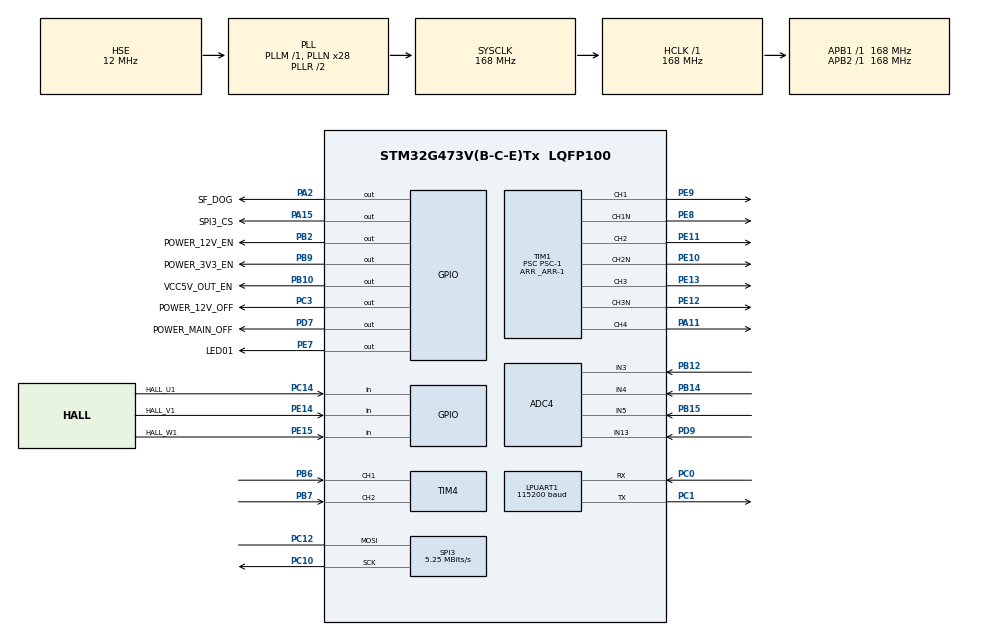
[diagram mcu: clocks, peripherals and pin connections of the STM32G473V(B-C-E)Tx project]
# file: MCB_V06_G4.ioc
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ADC4.Channel-5\#ChannelRegularConversion=ADC_CHANNEL_13
ADC4.EnableInjectedConversion=ENABLE
ADC4.ExternalTrigInjecConv=ADC_EXTERNALTRIGINJEC_T1_CC4
ADC4.InjNumberOfConversion=3
ADC4.InjectedChannel-6\#ChannelInjectedConversion=ADC_CHANNEL_3
ADC4.InjectedChannel-7\#ChannelInjectedConversion=ADC_CHANNEL_4
ADC4.InjectedChannel-8\#ChannelInjectedConversion=ADC_CHANNEL_5
ADC4.InjectedOffsetNumber-6\#ChannelInjectedConversion=ADC_OFFSET_NONE
ADC4.InjectedOffsetNumber-7\#ChannelInjectedConversion=ADC_OFFSET_NONE
ADC4.InjectedOffsetNumber-8\#ChannelInjectedConversion=ADC_OFFSET_NONE
ADC4.InjectedRank-6\#ChannelInjectedConversion=1
ADC4.InjectedRank-7\#ChannelInjectedConversion=2
ADC4.InjectedRank-8\#ChannelInjectedConversion=3
ADC4.InjectedSamplingTime-6\#ChannelInjectedConversion=ADC_SAMPLETIME_2CYCLES_5
ADC4.InjectedSamplingTime-7\#ChannelInjectedConversion=ADC_SAMPLETIME_2CYCLES_5
ADC4.InjectedSamplingTime-8\#ChannelInjectedConversion=ADC_SAMPLETIME_2CYCLES_5
ADC4.NbrOfConversionFlag=1
ADC4.OffsetNumber-5\#ChannelRegularConversion=ADC_OFFSET_NONE
ADC4.Rank-5\#ChannelRegularConversion=1
ADC4.Rank1_Channel=ADC_CHANNEL_3
ADC4.Rank2_Channel=ADC_CHANNEL_4
ADC4.Rank3_Channel=ADC_CHANNEL_5
ADC4.SamplingTime-5\#ChannelRegularConversion=ADC_SAMPLETIME_2CYCLES_5
Dma.LPUART1_RX.0.Direction=DMA_PERIPH_TO_MEMORY
Dma.LPUART1_RX.0.EventEnable=DISABLE
Dma.LPUART1_RX.0.Instance=DMA1_Channel1
Dma.LPUART1_RX.0.MemDataAlignment=DMA_MDATAALIGN_BYTE
Dma.LPUART1_RX.0.MemInc=DMA_MINC_ENABLE
Dma.LPUART1_RX.0.Mode=DMA_NORMAL
Dma.LPUART1_RX.0.PeriphDataAlignment=DMA_PDATAALIGN_BYTE
Dma.LPUART1_RX.0.PeriphInc=DMA_PINC_DISABLE
Dma.LPUART1_RX.0.Polarity=HAL_DMAMUX_REQ_GEN_RISING
Dma.LPUART1_RX.0.Priority=DMA_PRIORITY_LOW
Dma.LPUART1_RX.0.RequestNumber=1
Dma.LPUART1_RX.0.SignalID=NONE
Dma.LPUART1_RX.0.SyncEnable=DISABLE
Dma.LPUART1_RX.0.SyncPolarity=HAL_DMAMUX_SYNC_NO_EVENT
Dma.LPUART1_RX.0.SyncRequestNumber=1
Dma.LPUART1_RX.0.SyncSignalID=NONE
Dma.LPUART1_TX.1.Direction=DMA_MEMORY_TO_PERIPH
Dma.LPUART1_TX.1.EventEnable=DISABLE
Dma.LPUART1_TX.1.Instance=DMA1_Channel2
Dma.LPUART1_TX.1.MemDataAlignment=DMA_MDATAALIGN_BYTE
Dma.LPUART1_TX.1.MemInc=DMA_MINC_ENABLE
Dma.LPUART1_TX.1.Mode=DMA_NORMAL
Dma.LPUART1_TX.1.PeriphDataAlignment=DMA_PDATAALIGN_BYTE
Dma.LPUART1_TX.1.PeriphInc=DMA_PINC_DISABLE
Dma.LPUART1_TX.1.Polarity=HAL_DMAMUX_REQ_GEN_RISING
Dma.LPUART1_TX.1.Priority=DMA_PRIORITY_LOW
Dma.LPUART1_TX.1.RequestNumber=1
Dma.LPUART1_TX.1.SignalID=NONE
Dma.LPUART1_TX.1.SyncEnable=DISABLE
Dma.LPUART1_TX.1.SyncPolarity=HAL_DMAMUX_SYNC_NO_EVENT
Dma.LPUART1_TX.1.SyncRequestNumber=1
Dma.LPUART1_TX.1.SyncSignalID=NONE
Dma.Request0=LPUART1_RX
Dma.Request1=LPUART1_TX
LPUART1.BaudRate=115200
LPUART1.DataInvertParam=UART_ADVFEATURE_DATAINV_ENABLE
LPUART1.RxPinLevelInvertParam=UART_ADVFEATURE_RXINV_DISABLE
LPUART1.TxPinLevelInvertParam=UART_ADVFEATURE_TXINV_DISABLE
Mcu.Family=STM32G4
Mcu.Name=STM32G473V(B-C-E)Tx
Mcu.Package=LQFP100
Mcu.UserConstants=PSC,1;_ENCODERLINS,8192;_ARR,4200
NVIC.ADC4_IRQn=true\:0\:0\:false\:false\:true\:true\:true\:true
NVIC.DMA1_Channel2_IRQn=true\:0\:0\:false\:false\:true\:true\:true\:true
NVIC.LPUART1_IRQn=true\:0\:0\:false\:false\:true\:true\:true\:true
NVIC.PriorityGroup=NVIC_PRIORITYGROUP_4
NVIC.TIM1_UP_TIM16_IRQn=true\:0\:0\:false\:false\:true\:true\:true\:true
PA11.Signal=S_TIM1_CH4
PA13.Mode=Serial_Wire
PA13.Signal=SYS_JTMS-SWDIO
PA14.Mode=Serial_Wire
PA14.Signal=SYS_JTCK-SWCLK
PA15.GPIO_Label=SPI3_CS
PA15.GPIO_Speed=GPIO_SPEED_FREQ_LOW
PA15.Signal=GPIO_Output
PA2.GPIO_Label=SF_DOG
PA2.Signal=GPIO_Output
PB10.GPIO_Label=VCC5V_OUT_EN
PB10.Signal=GPIO_Output
PB12.Mode=IN3-Single-Ended
PB12.Signal=ADC4_IN3
PB14.Mode=IN4-Single-Ended
PB14.Signal=ADC4_IN4
PB15.Mode=IN5-Single-Ended
PB15.Signal=ADC4_IN5
PB2.GPIO_Label=POWER_12V_EN
PB2.Signal=GPIO_Output
PB6.Signal=S_TIM4_CH1
PB7.Signal=S_TIM4_CH2
PB9.GPIO_Label=POWER_3V3_EN
PB9.Signal=GPIO_Output
PC0.Mode=Asynchronous
PC0.Signal=LPUART1_RX
PC1.Mode=Asynchronous
PC1.Signal=LPUART1_TX
PC10.Mode=Simplex_Bidirectional_Master
PC10.Signal=SPI3_SCK
PC12.Mode=Simplex_Bidirectional_Master
PC12.Signal=SPI3_MOSI
PC14-OSC32_IN.GPIO_Label=HALL_U1
PC14-OSC32_IN.Signal=GPIO_Input
PC3.GPIO_Label=POWER_12V_OFF
PC3.Signal=GPIO_Output
PD7.GPIO_Label=POWER_MAIN_OFF
PD7.Signal=GPIO_Output
PD9.Mode=IN13-Single-Ended
PD9.Signal=ADC4_IN13
PE10.Mode=PWM Generation2 CH2 CH2N
PE10.Signal=TIM1_CH2N
PE11.Signal=S_TIM1_CH2
PE12.Mode=PWM Generation3 CH3 CH3N
PE12.Signal=TIM1_CH3N
PE13.Signal=S_TIM1_CH3
PE14.GPIO_Label=HALL_V1
PE14.Signal=GPIO_Input
PE15.GPIO_Label=HALL_W1
PE15.Signal=GPIO_Input
PE7.GPIO_Label=LED01
PE7.Signal=GPIO_Output
PE8.Mode=PWM Generation1 CH1 CH1N
PE8.Signal=TIM1_CH1N
PE9.Signal=S_TIM1_CH1
PF0-OSC_IN.Mode=HSE-External-Oscillator
PF0-OSC_IN.Signal=RCC_OSC_IN
PF1-OSC_OUT.Mode=HSE-External-Oscillator
PF1-OSC_OUT.Signal=RCC_OSC_OUT
ProjectManager.HeapSize=0x200
ProjectManager.StackSize=0x400
ProjectManager.TargetToolchain=Makefile
RCC.ADC12Freq_Value=168000000
RCC.ADC345Freq_Value=168000000
RCC.AHBFreq_Value=168000000
RCC.APB1Freq_Value=168000000
RCC.APB1TimFreq_Value=168000000
RCC.APB2Freq_Value=168000000
RCC.APB2TimFreq_Value=168000000
RCC.CortexFreq_Value=168000000
RCC.EXTERNAL_CLOCK_VALUE=12288000
RCC.HCLKFreq_Value=168000000
RCC.HSE_VALUE=12000000
RCC.HSI48_VALUE=48000000
RCC.HSI_VALUE=16000000
RCC.LSE_VALUE=32768
RCC.PLLN=28
RCC.PLLSourceVirtual=RCC_PLLSOURCE_HSE
RCC.SYSCLKFreq_VALUE=168000000
RCC.SYSCLKSource=RCC_SYSCLKSOURCE_PLLCLK
RCC.USBFreq_Value=168000000
RCC.VCOOutputFreq_Value=336000000
SH.S_TIM1_CH1.0=TIM1_CH1,PWM Generation1 CH1 CH1N
SH.S_TIM1_CH2.0=TIM1_CH2,PWM Generation2 CH2 CH2N
SH.S_TIM1_CH3.0=TIM1_CH3,PWM Generation3 CH3 CH3N
SH.S_TIM1_CH4.0=TIM1_CH4,Output Compare4 CH4
SH.S_TIM4_CH1.0=TIM4_CH1,Encoder_Interface
SH.S_TIM4_CH2.0=TIM4_CH2,Encoder_Interface
SPI3.BaudRatePrescaler=SPI_BAUDRATEPRESCALER_32
SPI3.CLKPhase=SPI_PHASE_2EDGE
SPI3.CRCCalculation=SPI_CRCCALCULATION_DISABLE
SPI3.CalculateBaudRate=5.25 MBits/s
SPI3.DataSize=SPI_DATASIZE_8BIT
SPI3.Direction=SPI_DIRECTION_1LINE
SPI3.Mode=SPI_MODE_MASTER
SPI3.VirtualType=VM_MASTER
TIM1.AutoReloadPreload=TIM_AUTORELOAD_PRELOAD_ENABLE
TIM1.Channel-Output\ Compare4\ CH4=TIM_CHANNEL_4
TIM1.Channel-PWM\ Generation1\ CH1\ CH1N=TIM_CHANNEL_1
TIM1.Channel-PWM\ Generation2\ CH2\ CH2N=TIM_CHANNEL_2
TIM1.Channel-PWM\ Generation3\ CH3\ CH3N=TIM_CHANNEL_3
TIM1.CounterMode=TIM_COUNTERMODE_CENTERALIGNED3
TIM1.OCMode_4=TIM_OCMODE_TOGGLE
TIM1.OCMode_PWM-PWM\ Generation1\ CH1\ CH1N=TIM_OCMODE_PWM2
TIM1.OCMode_PWM-PWM\ Generation2\ CH2\ CH2N=TIM_OCMODE_PWM2
TIM1.OCMode_PWM-PWM\ Generation3\ CH3\ CH3N=TIM_OCMODE_PWM2
TIM1.OCNPolarity_1=TIM_OCNPOLARITY_LOW
TIM1.OCNPolarity_2=TIM_OCNPOLARITY_LOW
TIM1.OCNPolarity_3=TIM_OCNPOLARITY_LOW
TIM1.PeriodNoDither=_ARR-1
TIM1.Prescaler=PSC-1
TIM1.PulseNoDither_4=200
TIM1.RepetitionCounter=2
TIM1.TIM_MasterOutputTrigger=TIM_TRGO_UPDATE
TIM1.TIM_MasterSlaveMode=TIM_MASTERSLAVEMODE_ENABLE
TIM4.Dithering=Disable
TIM4.EncoderMode=TIM_ENCODERMODE_CLOCKPLUSDIRECTION_X1
TIM4.IC1Filter=15
TIM4.IC1Polarity=TIM_ICPOLARITY_RISING
TIM4.IC2Filter=15
TIM4.PeriodNoDither=_ENCODERLINS-1
TIM4.SMS_Preload_Activation=DISABLE
VP_SYS_VS_DBSignals.Mode=DisableDeadBatterySignals
VP_TIM1_VS_ClockSourceINT.Mode=Internal
board=custom

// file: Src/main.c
/* USER CODE BEGIN Header */
/**
  ******************************************************************************
  * @file           : main.c
  * @brief          : Main program body
  ******************************************************************************
  * @attention
  *
  * Copyright (c) 2023 STMicroelectronics.
  * All rights reserved.
  *
  * This software is licensed under terms that can be found in the LICENSE file
  * in the root directory of this software component.
  * If no LICENSE file comes with this software, it is provided AS-IS.
  *
  ******************************************************************************
  */
/* USER CODE END Header */
#include "main.h"
#include "adc.h"
#include "dma.h"
#include "usart.h"
#include "spi.h"
#include "tim.h"
#include "gpio.h"

/* USER CODE BEGIN Includes */
#include "debuglog.h"
/* USER CODE END Includes */

void SystemClock_Config(void);

/* USER CODE BEGIN 0 */
extern void svpwm_testfunc(void);

/* USER CODE END 0 */

int main(void)
{

  /* MCU Configuration--------------------------------------------------------*/

  /* Reset of all peripherals, Initializes the Flash interface and the Systick. */
  HAL_Init();

  /* Configure the system clock */
  SystemClock_Config();

  /* Initialize all configured peripherals */
  MX_GPIO_Init();
  MX_DMA_Init();
  MX_SPI3_Init();
  MX_TIM1_Init();
  MX_ADC4_Init();
  MX_TIM4_Init();
  MX_LPUART1_UART_Init();
  /* USER CODE BEGIN 2 */
  HAL_Delay(800);
  USER_DEBUG_NORMAL("Hello world\n");
  // user_board_init();
  /* USER CODE END 2 */

  /* Infinite loop */
  /* USER CODE BEGIN WHILE */
  while (1)
  {
    // do_taskcalls();
    HAL_GPIO_TogglePin(SF_DOG_GPIO_Port,SF_DOG_Pin);
    static unsigned short count;
    if (count++>200)
    {
      count = 0;
      HAL_GPIO_TogglePin(LED01_GPIO_Port,LED01_Pin);
      USER_DEBUG_NORMAL(".\n");
    }
    svpwm_testfunc();
    HAL_Delay(1);
    /* USER CODE END WHILE */

  }
}

void SystemClock_Config(void)
{
  RCC_OscInitTypeDef RCC_OscInitStruct = {0};
  RCC_ClkInitTypeDef RCC_ClkInitStruct = {0};

  /** Configure the main internal regulator output voltage
  */
  HAL_PWREx_ControlVoltageScaling(PWR_REGULATOR_VOLTAGE_SCALE1_BOOST);

  /** Initializes the RCC Oscillators according to the specified parameters
  * in the RCC_OscInitTypeDef structure.
  */
  RCC_OscInitStruct.OscillatorType = RCC_OSCILLATORTYPE_HSE;
  RCC_OscInitStruct.HSEState = RCC_HSE_ON;
  RCC_OscInitStruct.PLL.PLLState = RCC_PLL_ON;
  RCC_OscInitStruct.PLL.PLLSource = RCC_PLLSOURCE_HSE;
  RCC_OscInitStruct.PLL.PLLM = RCC_PLLM_DIV1;
  RCC_OscInitStruct.PLL.PLLN = 28;
  RCC_OscInitStruct.PLL.PLLP = RCC_PLLP_DIV2;
  RCC_OscInitStruct.PLL.PLLQ = RCC_PLLQ_DIV2;
  RCC_OscInitStruct.PLL.PLLR = RCC_PLLR_DIV2;
  if (HAL_RCC_OscConfig(&RCC_OscInitStruct) != HAL_OK)
  {
    Error_Handler();
  }

  /** Initializes the CPU, AHB and APB buses clocks
  */
  RCC_ClkInitStruct.ClockType = RCC_CLOCKTYPE_HCLK|RCC_CLOCKTYPE_SYSCLK
                              |RCC_CLOCKTYPE_PCLK1|RCC_CLOCKTYPE_PCLK2;
  RCC_ClkInitStruct.SYSCLKSource = RCC_SYSCLKSOURCE_PLLCLK;
  RCC_ClkInitStruct.AHBCLKDivider = RCC_SYSCLK_DIV1;
  RCC_ClkInitStruct.APB1CLKDivider = RCC_HCLK_DIV1;
  RCC_ClkInitStruct.APB2CLKDivider = RCC_HCLK_DIV1;

  if (HAL_RCC_ClockConfig(&RCC_ClkInitStruct, FLASH_LATENCY_4) != HAL_OK)
  {
    Error_Handler();
  }
}

void Error_Handler(void)
{
  __disable_irq();
  while (1)
  {
  }
}
